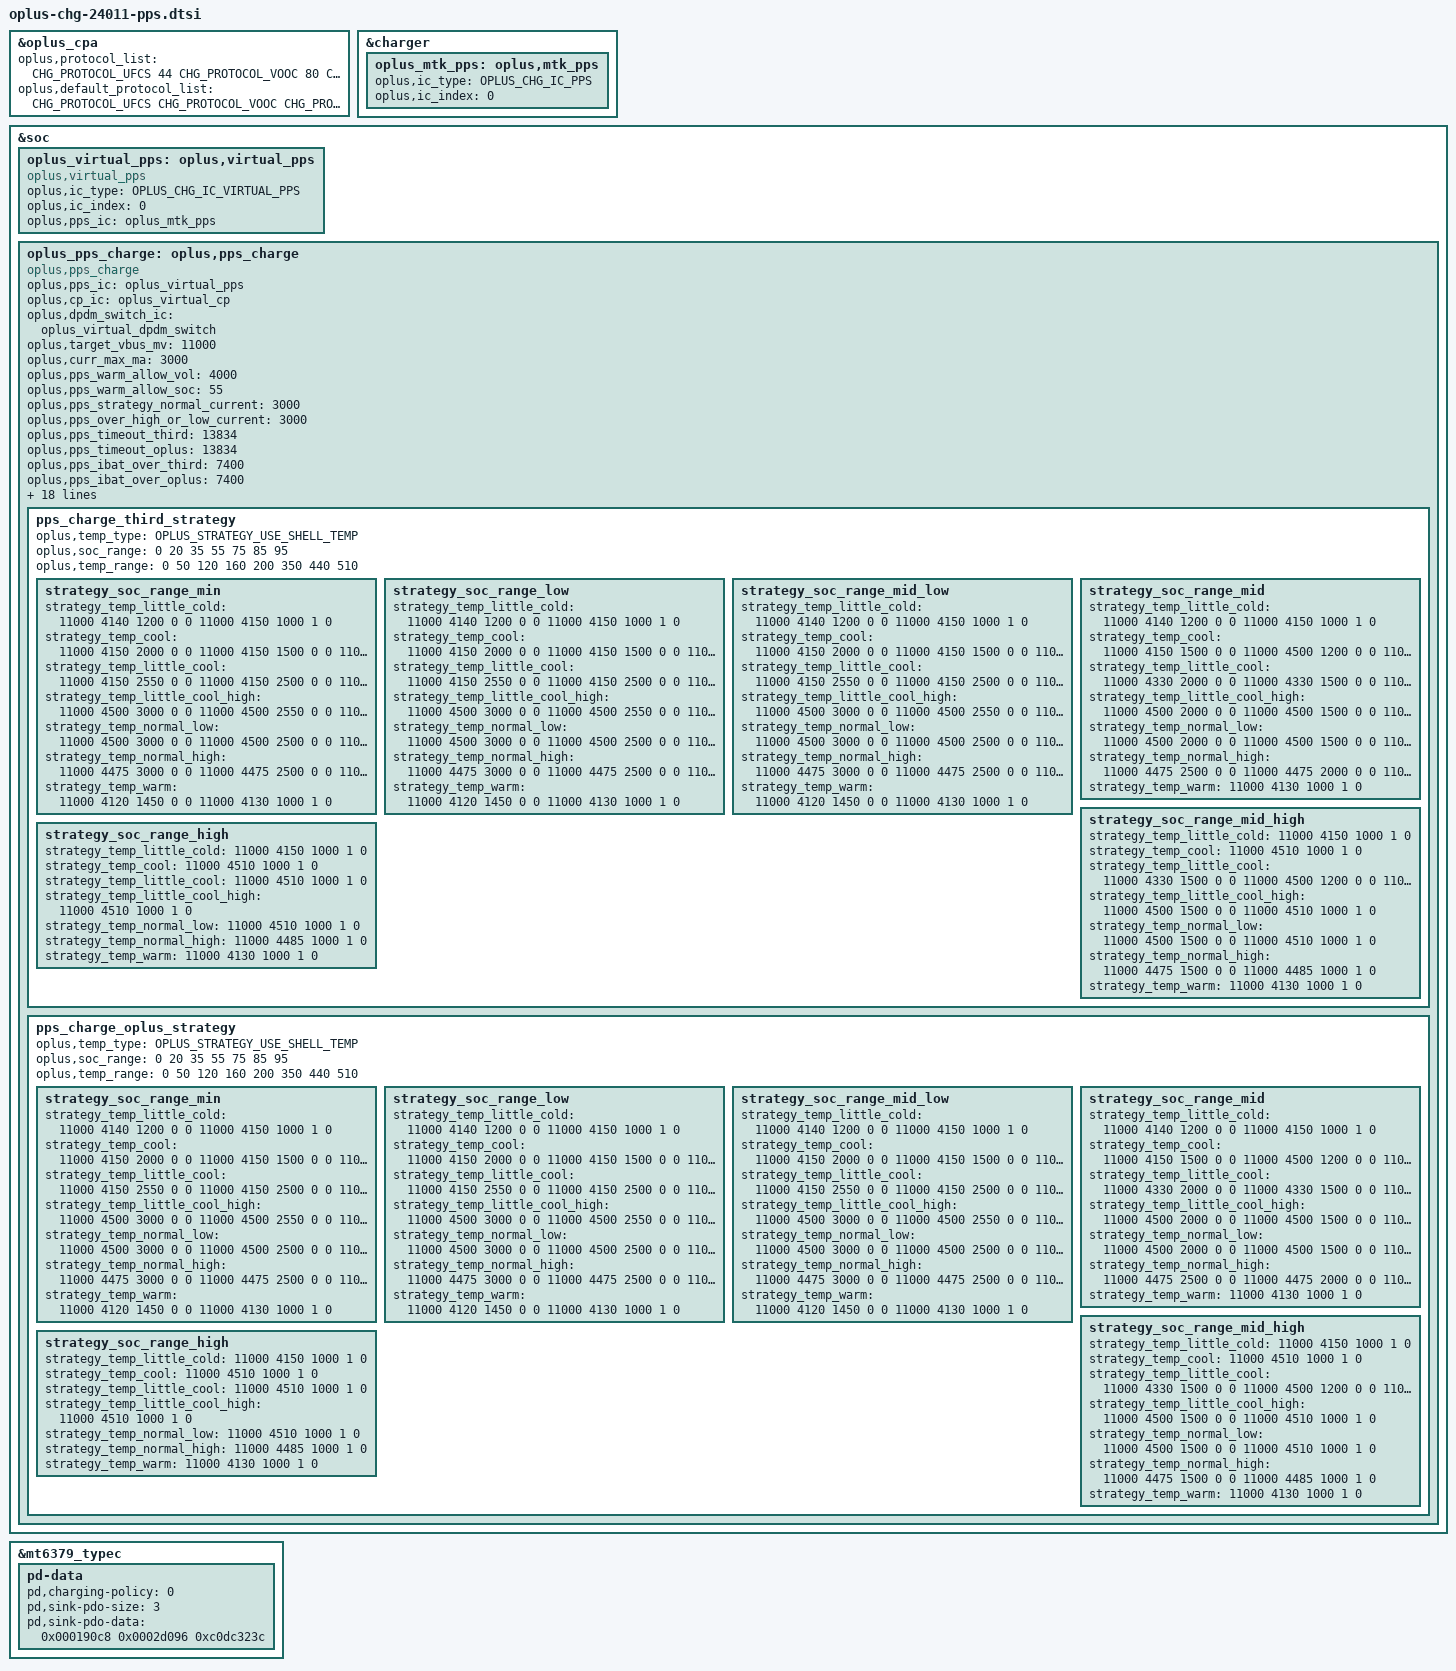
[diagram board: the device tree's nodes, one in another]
//ifdef OPLUS_FEATURE_CHG_BASIC
&oplus_cpa {
	oplus,protocol_list = <CHG_PROTOCOL_UFCS 44
			       CHG_PROTOCOL_VOOC 80
			       CHG_PROTOCOL_PPS 33
			       CHG_PROTOCOL_PD 18
			       CHG_PROTOCOL_QC 18>;
	oplus,default_protocol_list = <CHG_PROTOCOL_UFCS
				       CHG_PROTOCOL_VOOC
				       CHG_PROTOCOL_PPS
				       CHG_PROTOCOL_PD>;
};

&charger {
	oplus_mtk_pps: oplus,mtk_pps {
		oplus,ic_type = <OPLUS_CHG_IC_PPS>;
		oplus,ic_index = <0>;
	};
};
&soc {
	oplus_virtual_pps: oplus,virtual_pps {
		compatible = "oplus,virtual_pps";

		oplus,ic_type = <OPLUS_CHG_IC_VIRTUAL_PPS>;
		oplus,ic_index = <0>;
		oplus,pps_ic = <&oplus_mtk_pps>;
	};
	oplus_pps_charge: oplus,pps_charge {
		compatible = "oplus,pps_charge";
		oplus,pps_ic = <&oplus_virtual_pps>;
		oplus,cp_ic = <&oplus_virtual_cp>;
		oplus,dpdm_switch_ic = <&oplus_virtual_dpdm_switch>;

		oplus,target_vbus_mv = <11000>;
		oplus,curr_max_ma = <3000>;

		oplus,pps_warm_allow_vol = <4000>;
		oplus,pps_warm_allow_soc = <55>;
		oplus,pps_strategy_normal_current = <3000>;
		oplus,pps_over_high_or_low_current = <3000>;
		oplus,pps_timeout_third = <13834>;
		oplus,pps_timeout_oplus = <13834>;
		oplus,pps_ibat_over_third = <7400>;
		oplus,pps_ibat_over_oplus = <7400>;
		oplus,pps_full_cool_sw_vbat = <4510>;
		oplus,pps_full_normal_sw_vbat = <4510>;
		oplus,pps_full_normal_hw_vbat = <4540>;
		oplus,pps_full_warm_vbat = <4130>;
		oplus,pps_full_cool_sw_vbat_third = <4510>;
		oplus,pps_full_normal_sw_vbat_third= <4510>;
		oplus,pps_full_normal_hw_vbat_third = <4540>;
		oplus,pps_current_change_timeout = <100>;
		oplus,pps_strategy_batt_high_temp = <410 430 435 400 425 430>;
		oplus,pps_strategy_high_current = <3000 3000 2000 3000 3000 3000>;
		oplus,pps_little_cool_high_temp = <200>;
		oplus,curve_strategy_name = "pps_ufcs_curve_v2";
		oplus,pps_charge_strategy_soc = <0 20 35 55 75 85 95>;
		oplus,pps_charge_strategy_temp = <0 50 120 160 350 440 510>;

		pps_charge_third_strategy {
			oplus,temp_type = <OPLUS_STRATEGY_USE_SHELL_TEMP>;
			oplus,soc_range = <0 20 35 55 75 85 95>;
			oplus,temp_range = <0 50 120 160 200 350 440 510>;

			strategy_soc_range_min {
				strategy_temp_little_cold =	<11000 4140 1200 0 0
								11000 4150 1000 1 0>;
				strategy_temp_cool =		<11000 4150 2000 0 0
								11000 4150 1500 0 0
								11000 4500 1200 0 0
								11000 4500 1000 1 0>;
				strategy_temp_little_cool =	<11000 4150 2550 0 0
								11000 4150 2500 0 0
								11000 4330 2000 0 0
								11000 4330 1500 0 0
								11000 4500 1200 0 0
								11000 4510 1000 1 0>;
				strategy_temp_little_cool_high = <11000 4500 3000 0 0
								11000 4500 2550 0 0
								11000 4500 2500 0 0
								11000 4500 2000 0 0
								11000 4500 1500 0 0
								11000 4510 1000 1 0>;
				strategy_temp_normal_low =	<11000 4500 3000 0 0
								11000 4500 2500 0 0
								11000 4500 2000 0 0
								11000 4500 1500 0 0
								11000 4510 1000 1 0>;
				strategy_temp_normal_high =	<11000 4475 3000 0 0
								11000 4475 2500 0 0
								11000 4475 2000 0 0
								11000 4475 1500 0 0
								11000 4485 1000 1 0>;
				strategy_temp_warm =		<11000 4120 1450 0 0
								11000 4130 1000 1 0>;
			};
			strategy_soc_range_low {
				strategy_temp_little_cold =	<11000 4140 1200 0 0
								11000 4150 1000 1 0>;
				strategy_temp_cool =		<11000 4150 2000 0 0
								11000 4150 1500 0 0
								11000 4500 1200 0 0
								11000 4510 1000 1 0>;
				strategy_temp_little_cool =	<11000 4150 2550 0 0
								11000 4150 2500 0 0
								11000 4330 2000 0 0
								11000 4330 1500 0 0
								11000 4500 1200 0 0
								11000 4510 1000 1 0>;
				strategy_temp_little_cool_high = <11000 4500 3000 0 0
								11000 4500 2550 0 0
								11000 4500 2500 0 0
								11000 4500 2000 0 0
								11000 4500 1500 0 0
								11000 4510 1000 1 0>;
				strategy_temp_normal_low =	<11000 4500 3000 0 0
								11000 4500 2500 0 0
								11000 4500 2000 0 0
								11000 4500 1500 0 0
								11000 4510 1000 1 0>;
				strategy_temp_normal_high =	<11000 4475 3000 0 0
								11000 4475 2500 0 0
								11000 4475 2000 0 0
								11000 4475 1500 0 0
								11000 4485 1000 1 0>;
				strategy_temp_warm =		<11000 4120 1450 0 0
								11000 4130 1000 1 0>;
			};
			strategy_soc_range_mid_low {
				strategy_temp_little_cold =	<11000 4140 1200 0 0
								11000 4150 1000 1 0>;
				strategy_temp_cool =		<11000 4150 2000 0 0
								11000 4150 1500 0 0
								11000 4500 1200 0 0
								11000 4500 1000 1 0>;
				strategy_temp_little_cool =	<11000 4150 2550 0 0
								11000 4150 2500 0 0
								11000 4330 2000 0 0
								11000 4330 1500 0 0
								11000 4500 1200 0 0
								11000 4510 1000 1 0>;
				strategy_temp_little_cool_high = <11000 4500 3000 0 0
								11000 4500 2550 0 0
								11000 4500 2500 0 0
								11000 4500 2000 0 0
								11000 4500 1500 0 0
								11000 4510 1000 1 0>;
				strategy_temp_normal_low =	<11000 4500 3000 0 0
								11000 4500 2500 0 0
								11000 4500 2000 0 0
								11000 4500 1500 0 0
								11000 4510 1000 1 0>;
				strategy_temp_normal_high =	<11000 4475 3000 0 0
								11000 4475 2500 0 0
								11000 4475 2000 0 0
								11000 4475 1500 0 0
								11000 4485 1000 1 0>;
				strategy_temp_warm =		<11000 4120 1450 0 0
								11000 4130 1000 1 0>;
			};
			strategy_soc_range_mid {
				strategy_temp_little_cold =	<11000 4140 1200 0 0
								11000 4150 1000 1 0>;
				strategy_temp_cool =		<11000 4150 1500 0 0
								11000 4500 1200 0 0
								11000 4510 1000 1 0>;
				strategy_temp_little_cool =	<11000 4330 2000 0 0
								11000 4330 1500 0 0
								11000 4500 1200 0 0
								11000 4510 1000 1 0>;
				strategy_temp_little_cool_high = <11000 4500 2000 0 0
								11000 4500 1500 0 0
								11000 4510 1000 1 0>;
				strategy_temp_normal_low =	<11000 4500 2000 0 0
								11000 4500 1500 0 0
								11000 4510 1000 1 0>;
				strategy_temp_normal_high =	<11000 4475 2500 0 0
								11000 4475 2000 0 0
								11000 4475 1500 0 0
								11000 4485 1000 1 0>;
				strategy_temp_warm =		<11000 4130 1000 1 0>;
			};
			strategy_soc_range_mid_high {
				strategy_temp_little_cold =	<11000 4150 1000 1 0>;
				strategy_temp_cool =		<11000 4510 1000 1 0>;
				strategy_temp_little_cool =	<11000 4330 1500 0 0
								11000 4500 1200 0 0
								11000 4510 1000 1 0>;
				strategy_temp_little_cool_high = <11000 4500 1500 0 0
								11000 4510 1000 1 0>;
				strategy_temp_normal_low =	<11000 4500 1500 0 0
								11000 4510 1000 1 0>;
				strategy_temp_normal_high =	<11000 4475 1500 0 0
								11000 4485 1000 1 0>;
				strategy_temp_warm =		<11000 4130 1000 1 0>;
			};
			strategy_soc_range_high {
				strategy_temp_little_cold =	<11000 4150 1000 1 0>;
				strategy_temp_cool =		<11000 4510 1000 1 0>;
				strategy_temp_little_cool =	<11000 4510 1000 1 0>;
				strategy_temp_little_cool_high = <11000 4510 1000 1 0>;
				strategy_temp_normal_low =	<11000 4510 1000 1 0>;
				strategy_temp_normal_high =	<11000 4485 1000 1 0>;
				strategy_temp_warm =		<11000 4130 1000 1 0>;
			};
		};

		pps_charge_oplus_strategy {
			oplus,temp_type = <OPLUS_STRATEGY_USE_SHELL_TEMP>;
			oplus,soc_range = <0 20 35 55 75 85 95>;
			oplus,temp_range = <0 50 120 160 200 350 440 510>;

			strategy_soc_range_min {
				strategy_temp_little_cold =	<11000 4140 1200 0 0
								11000 4150 1000 1 0>;
				strategy_temp_cool =		<11000 4150 2000 0 0
								11000 4150 1500 0 0
								11000 4500 1200 0 0
								11000 4500 1000 1 0>;
				strategy_temp_little_cool =	<11000 4150 2550 0 0
								11000 4150 2500 0 0
								11000 4330 2000 0 0
								11000 4330 1500 0 0
								11000 4500 1200 0 0
								11000 4510 1000 1 0>;
				strategy_temp_little_cool_high = <11000 4500 3000 0 0
								11000 4500 2550 0 0
								11000 4500 2500 0 0
								11000 4500 2000 0 0
								11000 4500 1500 0 0
								11000 4510 1000 1 0>;
				strategy_temp_normal_low =	<11000 4500 3000 0 0
								11000 4500 2500 0 0
								11000 4500 2000 0 0
								11000 4500 1500 0 0
								11000 4510 1000 1 0>;
				strategy_temp_normal_high =	<11000 4475 3000 0 0
								11000 4475 2500 0 0
								11000 4475 2000 0 0
								11000 4475 1500 0 0
								11000 4485 1000 1 0>;
				strategy_temp_warm =		<11000 4120 1450 0 0
								11000 4130 1000 1 0>;
			};
			strategy_soc_range_low {
				strategy_temp_little_cold =	<11000 4140 1200 0 0
								11000 4150 1000 1 0>;
				strategy_temp_cool =		<11000 4150 2000 0 0
								11000 4150 1500 0 0
								11000 4500 1200 0 0
								11000 4510 1000 1 0>;
				strategy_temp_little_cool =	<11000 4150 2550 0 0
								11000 4150 2500 0 0
								11000 4330 2000 0 0
								11000 4330 1500 0 0
								11000 4500 1200 0 0
								11000 4510 1000 1 0>;
				strategy_temp_little_cool_high = <11000 4500 3000 0 0
								11000 4500 2550 0 0
								11000 4500 2500 0 0
								11000 4500 2000 0 0
								11000 4500 1500 0 0
								11000 4510 1000 1 0>;
				strategy_temp_normal_low =	<11000 4500 3000 0 0
								11000 4500 2500 0 0
								11000 4500 2000 0 0
								11000 4500 1500 0 0
								11000 4510 1000 1 0>;
				strategy_temp_normal_high =	<11000 4475 3000 0 0
								11000 4475 2500 0 0
								11000 4475 2000 0 0
								11000 4475 1500 0 0
								11000 4485 1000 1 0>;
				strategy_temp_warm =		<11000 4120 1450 0 0
								11000 4130 1000 1 0>;
			};
			strategy_soc_range_mid_low {
				strategy_temp_little_cold =	<11000 4140 1200 0 0
								11000 4150 1000 1 0>;
				strategy_temp_cool =		<11000 4150 2000 0 0
								11000 4150 1500 0 0
								11000 4500 1200 0 0
								11000 4500 1000 1 0>;
				strategy_temp_little_cool =	<11000 4150 2550 0 0
								11000 4150 2500 0 0
								11000 4330 2000 0 0
								11000 4330 1500 0 0
								11000 4500 1200 0 0
								11000 4510 1000 1 0>;
				strategy_temp_little_cool_high = <11000 4500 3000 0 0
								11000 4500 2550 0 0
								11000 4500 2500 0 0
								11000 4500 2000 0 0
								11000 4500 1500 0 0
								11000 4510 1000 1 0>;
				strategy_temp_normal_low =	<11000 4500 3000 0 0
								11000 4500 2500 0 0
								11000 4500 2000 0 0
								11000 4500 1500 0 0
								11000 4510 1000 1 0>;
				strategy_temp_normal_high =	<11000 4475 3000 0 0
								11000 4475 2500 0 0
								11000 4475 2000 0 0
								11000 4475 1500 0 0
								11000 4485 1000 1 0>;
				strategy_temp_warm =		<11000 4120 1450 0 0
								11000 4130 1000 1 0>;
			};
			strategy_soc_range_mid {
				strategy_temp_little_cold =	<11000 4140 1200 0 0
								11000 4150 1000 1 0>;
				strategy_temp_cool =		<11000 4150 1500 0 0
								11000 4500 1200 0 0
								11000 4510 1000 1 0>;
				strategy_temp_little_cool =	<11000 4330 2000 0 0
								11000 4330 1500 0 0
								11000 4500 1200 0 0
								11000 4510 1000 1 0>;
				strategy_temp_little_cool_high = <11000 4500 2000 0 0
								11000 4500 1500 0 0
								11000 4510 1000 1 0>;
				strategy_temp_normal_low =	<11000 4500 2000 0 0
								11000 4500 1500 0 0
								11000 4510 1000 1 0>;
				strategy_temp_normal_high =	<11000 4475 2500 0 0
								11000 4475 2000 0 0
								11000 4475 1500 0 0
								11000 4485 1000 1 0>;
				strategy_temp_warm =		<11000 4130 1000 1 0>;
			};
			strategy_soc_range_mid_high {
				strategy_temp_little_cold =	<11000 4150 1000 1 0>;
				strategy_temp_cool =		<11000 4510 1000 1 0>;
				strategy_temp_little_cool =	<11000 4330 1500 0 0
								11000 4500 1200 0 0
								11000 4510 1000 1 0>;
				strategy_temp_little_cool_high = <11000 4500 1500 0 0
								11000 4510 1000 1 0>;
				strategy_temp_normal_low =	<11000 4500 1500 0 0
								11000 4510 1000 1 0>;
				strategy_temp_normal_high =	<11000 4475 1500 0 0
								11000 4485 1000 1 0>;
				strategy_temp_warm =		<11000 4130 1000 1 0>;
			};
			strategy_soc_range_high {
				strategy_temp_little_cold =	<11000 4150 1000 1 0>;
				strategy_temp_cool =		<11000 4510 1000 1 0>;
				strategy_temp_little_cool =	<11000 4510 1000 1 0>;
				strategy_temp_little_cool_high = <11000 4510 1000 1 0>;
				strategy_temp_normal_low =	<11000 4510 1000 1 0>;
				strategy_temp_normal_high =	<11000 4485 1000 1 0>;
				strategy_temp_warm =		<11000 4130 1000 1 0>;
			};
		};
	};
};

&mt6379_typec {
	pd-data {
		pd,charging-policy = <0>;
		pd,sink-pdo-size = <3>;
		pd,sink-pdo-data = <0x000190c8 0x0002d096 0xc0dc323c>;
	};
};
//#endif OPLUS_FEATURE_CHG_BASIC
